# HDSC_HC32L157KX register map
Vendor: HDSC Co.Ltd; Series: ARMCM0P; File version: 1.2
CPU: CM0 r0p0, little endian, no MPU, no FPU, 3 interrupt priority bits
Registers are 8-bit, read-write, reset 0x0 unless marked. A register's access mark holds for its fields unless they carry their own. Offsets are from the block's base; [hi:lo] are bit positions; {n}, {i} and the like mark numbered series.

## DTIM1 — desc DTIM
Base 0x40015000
Same registers: DTIM2 0x40015020
0x00 TIMERLOAD 32-bit
0x04 TIMERVALUE 32-bit ro reset 0xFFFFFFFF
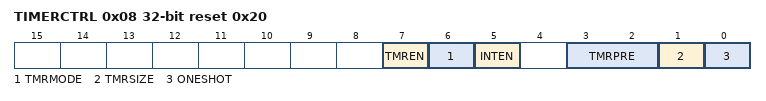
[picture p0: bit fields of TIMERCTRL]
0x08 TIMERCTRL 32-bit reset 0x20
  [7] TMREN, [6] TMRMODE, [5] INTEN, [3:2] TMRPRE, [1] TMRSIZE, [0] ONESHOT
0x0C TIMERINTCLR 32-bit wo reset 0xFFFFFFFF
0x10 TIMERRIS 32-bit ro
  [0] TMRINTST
0x14 TIMERMIS 32-bit ro
  [0] TMRMINTST
0x18 TIMERBGLOAD 32-bit

## EXTINT
Base 0x40030000
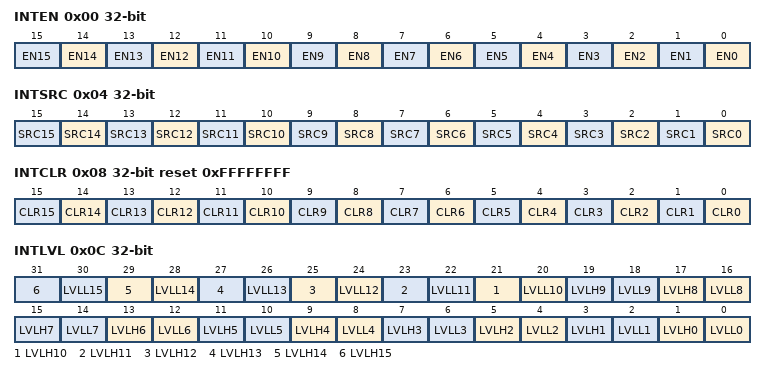
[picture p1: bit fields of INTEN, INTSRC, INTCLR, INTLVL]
0x00 INTEN 32-bit
  [n] EN{n} (n=0..15)
0x04 INTSRC 32-bit ro
  [n] SRC{n} (n=0..15)
0x08 INTCLR 32-bit reset 0xFFFFFFFF
  [n] CLR{n} (n=0..15)
0x0C INTLVL 32-bit
  [2n+1] LVLH{n} (n=0..15), [2n] LVLL{n} (n=0..15)
0x14 NMISRC 16-bit ro
  [0] SRC
0x18 NMICLR 16-bit reset 0x1
  [0] CLR

## FASTIO
Base 0xF8000000
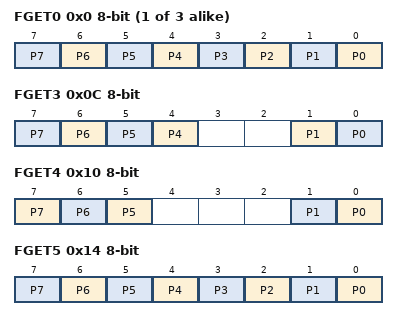
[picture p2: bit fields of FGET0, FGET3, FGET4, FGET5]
{0x0+4i} FGET{i} ro (i=0..2)
  [n] P{n} (n=0..7)
0x0C FGET3 ro
  [n] P{n} (n=4..7), [1] P1, [0] P0
0x10 FGET4 ro
  [7] P7, [6] P6, [5] P5, [1] P1, [0] P0
0x14 FGET5 ro
  [n] P{n} (n=0..7)
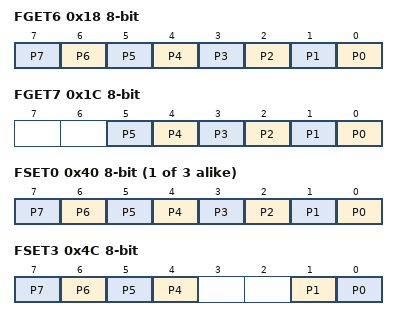
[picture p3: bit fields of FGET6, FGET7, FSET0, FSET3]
0x18 FGET6 ro
  [n] P{n} (n=0..7)
0x1C FGET7 ro (reset mask 0x1F)
  [n] P{n} (n=0..5)
0x20 FGET8 ro
  [0] P0
{0x40+4i} FSET{i} (i=0..2)
  [n] P{n} (n=0..7)
0x4C FSET3
  [n] P{n} (n=4..7), [1] P1, [0] P0
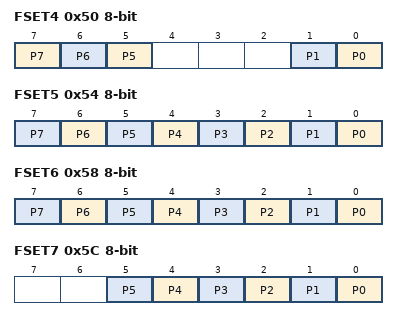
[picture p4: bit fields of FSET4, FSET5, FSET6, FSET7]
0x50 FSET4
  [7] P7, [6] P6, [5] P5, [1] P1, [0] P0
0x54 FSET5
  [n] P{n} (n=0..7)
0x58 FSET6
  [n] P{n} (n=0..7)
0x5C FSET7 (reset mask 0x1F)
  [n] P{n} (n=0..5)
0x60 FSET8
  [0] P0

## FLASH
Base 0x40000000
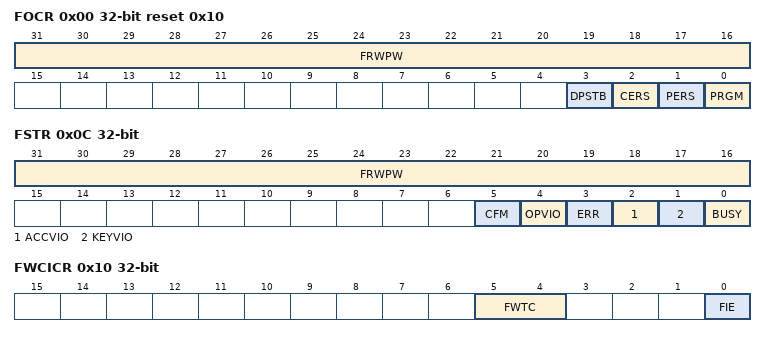
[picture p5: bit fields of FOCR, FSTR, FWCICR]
0x00 FOCR 32-bit reset 0x10
  [31:16] FRWPW, [3] DPSTB, [2] CERS, [1] PERS, [0] PRGM
0x04 FLCR0 32-bit reset 0xFFFFFFFF
  [31:0] LOCK2K
0x08 FLCR1 32-bit reset 0xFFFFFFFF
  [31:0] LOCK2K
0x0C FSTR 32-bit
  [31:16] FRWPW, [5] CFM, [4] OPVIO, [3] ERR, [2] ACCVIO, [1] KEYVIO, [0] BUSY ro
0x10 FWCICR 32-bit
  [5:4] FWTC, [0] FIE
{0x14+4i} FUDR{i} 32-bit ro (i=0..3)
  [31:0] UD{i}
0x24 TNVS reset 0x18
0x28 TPROG reset 0x18
0x2C TPGS reset 0x18
0x30 TRCVPGM reset 0x18
0x34 TRCVPERS reset 0x19
0x38 TRCVCERS reset 0x7
0x3C TPERS reset 0x10
0x40 TCERS reset 0x20

## HWWDT
Base 0x40011000
0x00 WDT_LD 32-bit reset 0xFFFF
0x04 WDT_VL 32-bit ro
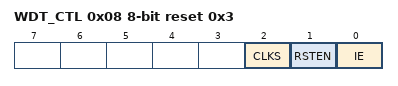
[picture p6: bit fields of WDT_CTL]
0x08 WDT_CTL reset 0x3
  [2] CLKS, [1] RSTEN, [0] IE
0x0C WDT_INTCLR
0x10 WDT_STA ro
  [0] STA
0x14 WDT_LCK 32-bit reset 0x1

## IRQC
Base 0x40031000
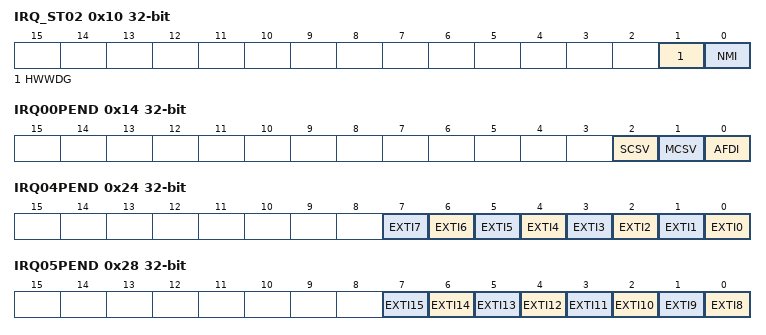
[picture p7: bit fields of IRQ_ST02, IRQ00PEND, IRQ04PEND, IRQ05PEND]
0x10 IRQ_ST02 32-bit ro
  [1] HWWDG, [0] NMI
0x14 IRQ00PEND 32-bit ro
  [2] SCSV, [1] MCSV, [0] AFDI
0x18 IRQ01PEND 32-bit ro
  [0] SWWDG
0x1C IRQ02PEND 32-bit ro
  [0] LVD
0x24 IRQ04PEND 32-bit ro
  [n] EXTI{n} (n=0..7)
0x28 IRQ05PEND 32-bit ro
  [n-8] EXTI{n} (n=8..15)
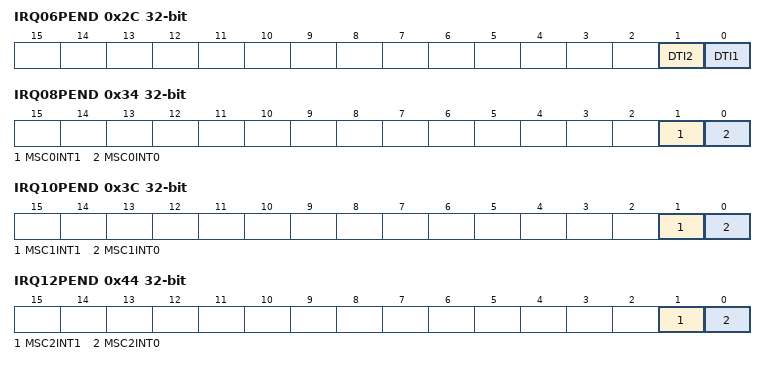
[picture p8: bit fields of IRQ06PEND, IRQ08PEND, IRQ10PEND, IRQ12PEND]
0x2C IRQ06PEND 32-bit ro
  [1] DTI2, [0] DTI1
0x30 IRQ07PEND 32-bit ro
  [0] MSC0INT
0x34 IRQ08PEND 32-bit ro
  [1] MSC0INT1, [0] MSC0INT0
0x38 IRQ09PEND 32-bit ro
  [0] MSC1INT
0x3C IRQ10PEND 32-bit ro
  [1] MSC1INT1, [0] MSC1INT0
0x40 IRQ11PEND 32-bit ro
  [0] MSC2INT
0x44 IRQ12PEND 32-bit ro
  [1] MSC2INT1, [0] MSC2INT0
0x50 IRQ15PEND 32-bit ro
  [0] MSC4INT
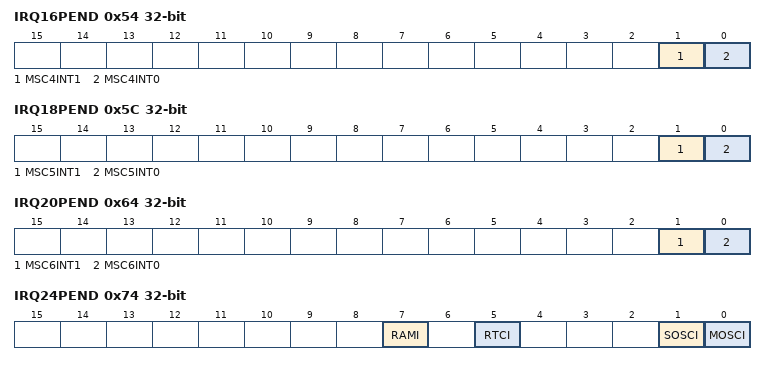
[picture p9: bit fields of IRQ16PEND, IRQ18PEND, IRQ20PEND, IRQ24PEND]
0x54 IRQ16PEND 32-bit ro
  [1] MSC4INT1, [0] MSC4INT0
0x58 IRQ17PEND 32-bit ro
  [0] MSC5INT
0x5C IRQ18PEND 32-bit ro
  [1] MSC5INT1, [0] MSC5INT0
0x60 IRQ19PEND 32-bit ro
  [0] MSC6INT
0x64 IRQ20PEND 32-bit ro
  [1] MSC6INT1, [0] MSC6INT0
0x74 IRQ24PEND 32-bit ro
  [7] RAMI, [5] RTCI, [1] SOSCI, [0] MOSCI
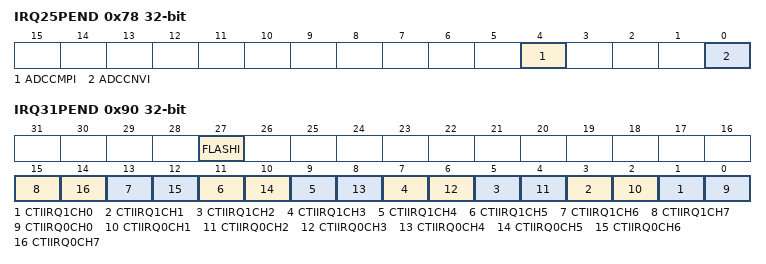
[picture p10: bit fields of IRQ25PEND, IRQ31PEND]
0x78 IRQ25PEND 32-bit ro
  [4] ADCCMPI, [0] ADCCNVI
0x7C IRQ26PEND 32-bit ro
  [5] VCI
0x80 IRQ27PEND 32-bit ro
  [6] ICCI
0x90 IRQ31PEND 32-bit ro
  [27] FLASHI, [2n+1] CTIIRQ1CH{n} (n=0..7), [2n] CTIIRQ0CH{n} (n=0..7)

## LCDC
Base 0x40032000
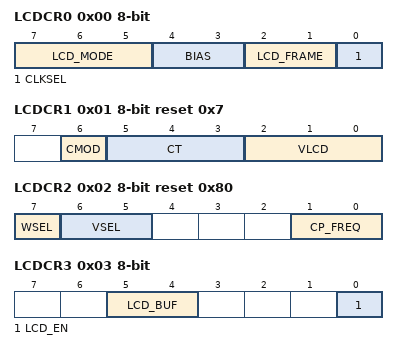
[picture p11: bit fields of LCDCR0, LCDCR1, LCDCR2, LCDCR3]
0x00 LCDCR0
  [7:5] LCD_MODE, [4:3] BIAS, [2:1] LCD_FRAME, [0] CLKSEL
0x01 LCDCR1 reset 0x7
  [6] CMOD, [5:3] CT, [2:0] VLCD
0x02 LCDCR2 reset 0x80
  [7] WSEL, [6:5] VSEL, [1:0] CP_FREQ
0x03 LCDCR3
  [5:4] LCD_BUF, [0] LCD_EN
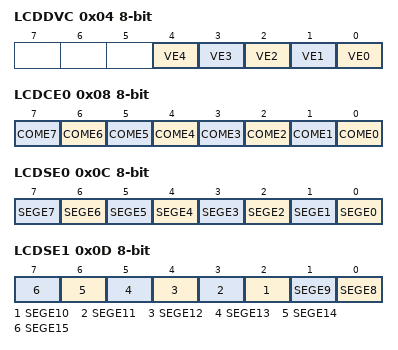
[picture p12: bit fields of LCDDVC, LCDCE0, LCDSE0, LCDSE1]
0x04 LCDDVC
  [n] VE{n} (n=0..4)
0x08 LCDCE0
  [n] COME{n} (n=0..7)
0x0C LCDSE0
  [n] SEGE{n} (n=0..7)
0x0D LCDSE1
  [n-8] SEGE{n} (n=8..15)
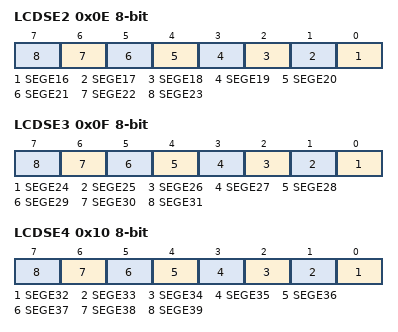
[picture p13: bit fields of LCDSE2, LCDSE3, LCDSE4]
0x0E LCDSE2
  [n-16] SEGE{n} (n=16..23)
0x0F LCDSE3
  [n-24] SEGE{n} (n=24..31)
0x10 LCDSE4
  [n-32] SEGE{n} (n=32..39)
{0x14+i} LCDRAM{i:02} (i=0..39)
